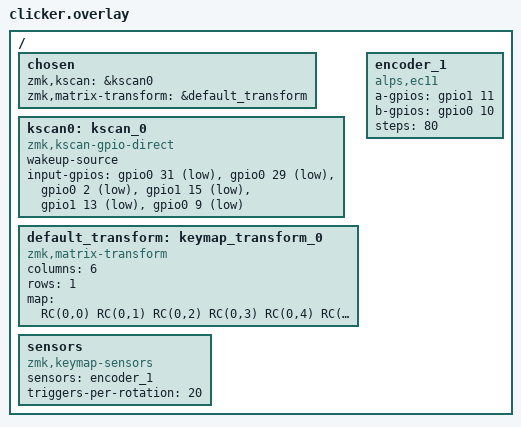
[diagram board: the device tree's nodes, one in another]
#include <dt-bindings/zmk/matrix_transform.h>

/ {
    chosen {
        zmk,kscan = &kscan0;
        zmk,matrix-transform = &default_transform;
    };

    kscan0: kscan_0 {
        compatible = "zmk,kscan-gpio-direct";
        wakeup-source;
        input-gpios
            = <&gpio0 31 (GPIO_ACTIVE_LOW | GPIO_PULL_UP)> // SW1 (031)
            , <&gpio0 29 (GPIO_ACTIVE_LOW | GPIO_PULL_UP)> // SW2 (029)
            , <&gpio0 2 (GPIO_ACTIVE_LOW | GPIO_PULL_UP)>  // SW3 (002)
            , <&gpio1 15 (GPIO_ACTIVE_LOW | GPIO_PULL_UP)> // SW4 (115)
            , <&gpio1 13 (GPIO_ACTIVE_LOW | GPIO_PULL_UP)> // SW5 (113)
            , <&gpio0 9 (GPIO_ACTIVE_LOW | GPIO_PULL_UP)>  // Encoder Button (009)
            ;
    };

    default_transform: keymap_transform_0 {
        compatible = "zmk,matrix-transform";
        columns = <6>;
        rows = <1>;
        map = <
            RC(0,0) RC(0,1) RC(0,2) RC(0,3) RC(0,4) RC(0,5)
        >;
    };

    encoder_1: encoder_1 {
        compatible = "alps,ec11";
        a-gpios = <&gpio1 11 (GPIO_ACTIVE_HIGH | GPIO_PULL_UP)>; // 111
        b-gpios = <&gpio0 10 (GPIO_ACTIVE_HIGH | GPIO_PULL_UP)>; // 010
        steps = <80>;
        status = "okay";
    };

    sensors: sensors {
        compatible = "zmk,keymap-sensors";
        sensors = <&encoder_1>;
        triggers-per-rotation = <20>;
    };
};
